# gcr_me13 register map
Registers are access not given, no defined reset value unless marked. A register's access mark holds for its fields unless they carry their own. Offsets are from the block's base; lines under a group give offsets from that group; [hi:lo] are bit positions; {n}, {i} and the like mark numbered series; 'fields as' and 'values as' point back to an identical list; <NAME> marks a mode.

## Memory map
0x40000000 GCR size 0x400 — Global Control Registers.

## GCR — Global Control Registers.
Base 0x40000000
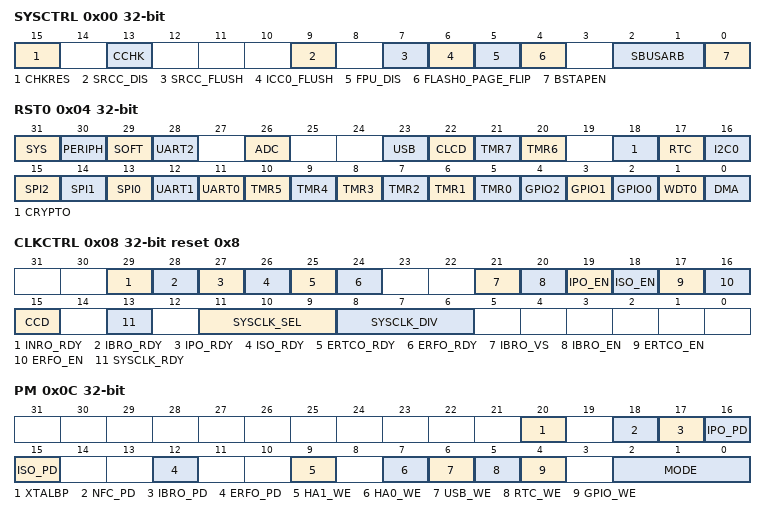
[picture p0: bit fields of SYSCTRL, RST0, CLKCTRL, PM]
0x00 SYSCTRL — System Control.
  [15] CHKRES — ROM Checksum Result. This bit is only valid when CHKRD=1.
    0=pass (ROM Checksum Correct.); 1=fail (ROM Checksum Fail.)
  [13] CCHK — Compute ROM Checksum. This bit is self-cleared when calculation is completed. Once set, software clearing this bit is ignored and the bit will remain set until the operation is completed.
    0=complete (No operation/complete.); 1=Start operation
  [9] SRCC_DIS — Data Cache Disable. The system cache (s) will be completely disabled when this bit is set.
    0=en (Is enabled.); 1=dis (Is Disabled.)
  [7] SRCC_FLUSH — Data Cache Flush. The system cache (s) will be flushed when this bit is set.
    0=Normal System Cache Operation; 1=flush (System Cache is flushed)
  [6] ICC0_FLUSH — Code Cache Flush. This bit is used to flush the code caches and the instruction buffer of the Cortex-M4.
    0=Normal Code Cache Operation; 1=flush (Code Caches and CPU instruction buffer are flushed)
  [5] FPU_DIS — Cortex M4 Floating Point Disable This bit is used to disable the floating-point unit of the Cortex-M4.
  [4] FLASH0_PAGE_FLIP — Flips the Flash bottom and top halves. (Depending on the total flash size, each half is either 256K or 512K). Initiating a flash page flip will cause a flush of both the data buffer on the DCODE bus and the internal instruction buffer.
    0=normal (Physical layout matches logical layout.); 1=swapped (Bottom half mapped to logical top half and vice versa.)
  [2:1] SBUSARB — System bus abritration scheme. These bits are used to select between Fixed-burst abritration and Round-Robin scheme. The Round-Robin scheme is selected by default. These bits are reset by the system reset.
    0=fix (Fixed Burst abritration.); 1=Round-robin scheme
  [0] BSTAPEN — Boundary Scan TAP enable. When enabled, the JTAG port is connected to the Boundary Scan TAP. Otherwise, the port is connected to the ARM ICE function. This bit is reset by the POR. Reset value and access depend on the part number.
    0=dis (Boundary Scan TAP port disabled.); 1=en (Boundary Scan TAP port enabled.)
0x04 RST0 — Reset.
  [31] SYS — System Reset. Setting this bit to 1 resets the CPU core and all peripherals, including the watchdog timer.
  [30] PERIPH — Peripheral Reset. Setting this bit to 1 resets all peripherals. The CPU core, the watchdog timer, and all GPIO pins are unaffected by this reset.
  [29] SOFT — Soft Reset. Setting this bit to 1 resets everything except the CPU and the watchdog timer.
  [28] UART2 — UART2 Reset. Setting this bit to 1 resets all UART 2 blocks.
  [26] ADC — Analog to Digital Reset.
  [23] USB — USB Reset. Setting this bit resets both USB blocks.
  [22] CLCD — CLCD Reset. Setting this bit to 1 resets the CLCD block.
  [21] TMR7 — Timer7 Reset. Setting this bit to 1 resets Timer 7 blocks.
  [20] TMR6 — Timer6 Reset. Setting this bit to 1 resets Timer 6 blocks.
  [18] CRYPTO — Cryptographic Reset. Setting this bit to 1 resets the AES block, the SHA block and the DES block.
  [17] RTC — Real Time Clock Reset.
  [16] I2C0 — I2C0 Reset.
  [15] SPI2 — SPI2 Reset. Setting this bit to 1 resets all SPI 2 blocks.
  [14] SPI1 — SPI1 Reset. Setting this bit to 1 resets all SPI 1 blocks.
  [13] SPI0 — SPI0 Reset. Setting this bit to 1 resets all SPI 0 blocks.
  [12] UART1 — UART1 Reset. Setting this bit to 1 resets all UART 1 blocks.
  [11] UART0 — UART0 Reset. Setting this bit to 1 resets all UART 0 blocks.
  [n+5] TMR{n} (n=0..5) — Timer{n} Reset. Setting this bit to 1 resets Timer {n} blocks.
  [4] GPIO2 — GPIO2 Reset. Setting this bit to 1 resets GPIO2 pins to their default states.
  [3] GPIO1 — GPIO1 Reset. Setting this bit to 1 resets GPIO1 pins to their default states.
  [2] GPIO0 — GPIO0 Reset. Setting this bit to 1 resets GPIO0 pins to their default states.
  [1] WDT0 — Watchdog Timer Reset.
  [0] DMA — DMA Reset.
0x08 CLKCTRL reset 0x8 — Clock Control.
  [29] INRO_RDY ro — Internal Nano Ring Oscillator Low Frequency Reference Clock Ready.
    0=not (Is not Ready.); 1=ready (Is Ready.)
  [28] IBRO_RDY ro — Internal Baud Rate Oscillator Ready.
    0=not (Is not Ready.); 1=ready (Is Ready.)
  [27] IPO_RDY ro — Internal Primary Oscillator Ready.
    0=not (Is not Ready.); 1=ready (Is Ready.)
  [26] ISO_RDY ro — 60MHz ISO Ready.
    0=not (Is not Ready.); 1=ready (Is Ready.)
  [25] ERTCO_RDY ro — 32kHz Crystal Oscillator Ready
    0=not (Is not Ready.); 1=ready (Is Ready.)
  [24] ERFO_RDY ro — 27MHz Crystal Oscillator Ready
    0=not (Is not Ready.); 1=ready (Is Ready.)
  [21] IBRO_VS — 7.3728MHz Internal Oscillator Voltage Source Select
  [20] IBRO_EN — 8MHz High Frequency Internal Reference Clock Enable.
  [19] IPO_EN — 96MHz High Frequency Internal Reference Clock Enable.
  [18] ISO_EN — 60MHz High Frequency Internal Reference Clock Enable.
  [17] ERTCO_EN — 32kHz Crystal Oscillator Enable.
  [16] ERFO_EN — 27MHz Crystal Oscillator Enable.
    0=dis (Is Disabled.); 1=en (Is Enabled.)
  [15] CCD ro — Cryptographic clock divider
    0=non_div (The cryptographic accelerator clock is running in non-divided mode.); 1=div (The cryptographic accelerator clock is running in divided mode.)
  [13] SYSCLK_RDY ro — Clock Ready. This read only bit reflects whether the currently selected system clock source is running.
    0=busy (Switchover to the new clock source (as selected by CLKSEL) has not yet occurred.); 1=ready (System clock running from CLKSEL clock source.)
  [11:9] SYSCLK_SEL — Clock Source Select. This 3 bit field selects the source for the system clock.
    0=ISO (Internal Secondary Oscilatior Clock); 2=ERFO (27MHz Crystal is used for the system clock.); 3=INRO (8kHz Internal Nano Ring Oscillator is used for the system clock.); 4=IPO (The internal Primary oscillator is used for the system clock.); 5=IBRO (The internal Baud Rate oscillator is used for the system clock.); 6=ERTCO (32kHz is used for the system clock.)
  [8:6] SYSCLK_DIV — Prescaler Select. This 3 bit field sets the system operating frequency by controlling the prescaler that divides the output of the PLL0.
    0=div1 (Divide by 1.); 1=div2 (Divide by 2.); 2=div4 (Divide by 4.); 3=div8 (Divide by 8.); 4=div16 (Divide by 16.); 5=div32 (Divide by 32.); 6=div64 (Divide by 64.); 7=div128 (Divide by 128.)
0x0C PM — Power Management.
  [20] XTALBP — XTAL Bypass
    0=normal; 1=bypass
  [18] NFC_PD — When set, the NFC radio becomes inactive when the upon entering DEEPSLEEP mode
    0=active (Mode is Active.); 1=deepsleep (Powered down in DEEPSLEEP.)
  [17] IBRO_PD — Internal Baud Rate Oscillator power down. This bit selects the power state in DEEPSLEEP mode.
    values as NFC_PD
  [16] IPO_PD — Internal Primary Oscilatory power down. This bit selects the power state in DEEPSLEEP mode.
    values as NFC_PD
  [15] ISO_PD — Internal Secondary Oscilator Power Down. This bit selects the power state in DEEPSLEEP mode.
    values as NFC_PD
  [12] ERFO_PD — Radio Frequency oscilator Crystal Power Down. This bit selects the power state in DEEPSLEEP mode.
    values as NFC_PD
  [9] HA1_WE — Hardware Accelerator 1 Wake Up Enable. This bit enables USB activity as wakeup source.
  [7] HA0_WE — Hardware Accelerator 0 Wake Up Enable. This bit enables USB activity as wakeup source.
  [6] USB_WE — USB Wake Up Enable. This bit enables USB activity as wakeup source.
  [5] RTC_WE — RTC Alarm Wake Up Enable. This bit enables RTC alarm as wakeup source. If enabled, the desired RTC alarm must be configured via the RTC control registers.
  [4] GPIO_WE — GPIO Wake Up Enable. This bit enables all GPIO pins as potential wakeup sources. Any GPIO configured for wakeup is capable of causing an exit from IDLE or STANDBY modes when this bit is set.
  [2:0] MODE — Operating Mode. This two bit field selects the current operating mode for the device. Note that code execution only occurs during ACTIVE mode.
    0=Active Mode; 2=DeepSleep Mode; 3=Shutdown Mode; 4=Backup Mode
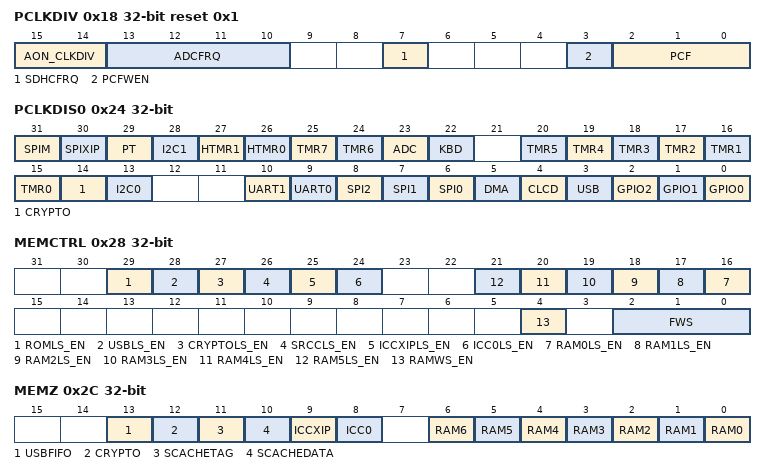
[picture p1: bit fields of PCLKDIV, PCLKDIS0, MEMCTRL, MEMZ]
0x18 PCLKDIV reset 0x1 — Peripheral Clock Divider.
  [15:14] AON_CLKDIV — Always-ON (AON) domain CLock Divider. These bits define the AON domain clock divider.
    0=div_4 (PCLK divide by 4.); 1=div_8 (PCLK divide by 8.); 2=div_16 (PCLK divide by 16.); 3=div_32 (PCLK divide by 32.)
  [13:10] ADCFRQ — ADC clock Frequency. These bits define the ADC clock frequency. FADC = FPCLK/ (ADCFRQ).
  [7] SDHCFRQ — SDHC Clock Frequency. This bits defines the clock frequency of SDHC.
    0=48MHz; 1=24MHz
  [3] PCFWEN — PCF Write Enable. This bit allows the PCF Register bits to be updated by Software.
    0=blocked (Writes to PCF are blocked.); 1=allowed (Writes to PCF are allowed)
  [2:0] PCF — These bits determine the clock frequency for the UART, I2C and Key Pad peripherals. These peripherals have an adaptive clock generator that dynamically adjusts the peripheral frequency based on the main system bus frequency. These bits are dynamically updated when the PLL0 is selected as the system clock source and are set by hardware. These bits determine the clock frequency for the UART, I2C and Key Pad peripherals. These peripherals have an adaptive clock generator that dynamically adjusts the peripheral frequency based on the main system bus frequency. These bits are dynamically updated when the PLL0 is selected as the system clock source and are set by hardware.
    2=96MHz; 3=48MHz; 4=24MHz; 5=12MHz; 6=6MHz; 7=3MHz
0x24 PCLKDIS0 — Peripheral Clock Disable.
  [all] fields
    0=en (enable it.); 1=dis (disable it.)
  [31] SPIM — SPI XiP Master Controller Disable.
  [30] SPIXIP — SPI XiP Disable.
  [29] PT — PT Clock Disable.
  [28] I2C1 — I2C 1 Disable.
  [27] HTMR1 — HTimer 1 Disable.
  [26] HTMR0 — HTimer 0 Disable.
  [25] TMR7 — Timer 7 Disable.
  [24] TMR6 — Timer 6 Disable.
  [23] ADC — ADC Disable.
  [22] KBD — Secure Keyboard Disable.
  [n+15] TMR{n} (n=0..5) — Timer {n} Disable.
  [14] CRYPTO — Crypto Disable.
  [13] I2C0 — I2C 0 Disable.
  [10] UART1 — UART 1 Disable.
  [9] UART0 — UART 0 Disable.
  [8] SPI2 — SPI 2 Disable.
  [7] SPI1 — SPI 1 Disable.
  [6] SPI0 — SPI 0 Disable.
  [5] DMA — DMA Disable.
  [4] CLCD — CLCD Disable.
  [3] USB — USB Disable.
  [2] GPIO2 — GPIO2 Disable.
  [1] GPIO1 — GPIO1 Disable.
  [0] GPIO0 — GPIO0 Clock Disable.
0x28 MEMCTRL — Memory Clock Control Register.
  [29] ROMLS_EN — ROM Light Sleep Mode.
    0=active (RAM is active.); 1=light_sleep (RAM is in Light Sleep mode.)
  [28] USBLS_EN — USB FIFO Light Sleep Mode.
    values as ROMLS_EN
  [27] CRYPTOLS_EN — CRYPTO RAM Light Sleep Mode.
    values as ROMLS_EN
  [26] SRCCLS_EN — SysCache RAM Light Sleep Mode.
    values as ROMLS_EN
  [25] ICCXIPLS_EN — ICACHE-XIP RAM Light Sleep Mode.
    values as ROMLS_EN
  [24] ICC0LS_EN — ICache RAM Light Sleep Mode.
    values as ROMLS_EN
  [n+16] RAM{n}LS_EN (n=0..5) — System RAM {n} Light Sleep Mode.
    values as ROMLS_EN
  [4] RAMWS_EN — SRAM Wait State Enable
  [2:0] FWS — Flash Wait State. These bits define the number of wait-state cycles per Flash data read access. Minimum wait state is 2.
0x2C MEMZ — Memory Zeroize Control.
  [all] fields
    0=nop (No operation/complete.); 1=Start operation
  [13] USBFIFO — USB FIFO Zeroization.
  [12] CRYPTO — Crypto (MAA) Memory.
  [11] SCACHETAG — System Cache Tag Zeroization.
  [10] SCACHEDATA — System Cache Data Ram Zeroization.
  [9] ICCXIP — Instruction Cache XIP Data and Tag Ram zeroizatoin.
  [8] ICC0 — Instruction Cache.
  [n] RAM{n} (n=0..6) — System RAM Block {n}.
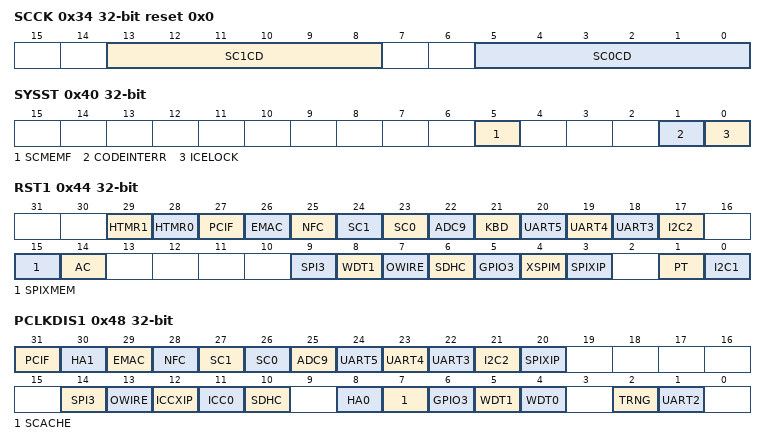
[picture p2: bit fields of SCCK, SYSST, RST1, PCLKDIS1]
0x34 SCCK reset 0x0 — Smart Card Clock Control.
  [13:8] SC1CD — Smart Card1 Clock Divider
  [5:0] SC0CD — Smart Card0 Clock Divider
0x40 SYSST — System Status Register.
  [5] SCMEMF — System Cache Memory Fault Flag. This bit indicates a memory fault has occurred in the System Cache while receiving data from the Hyperbus Interface.
    0=Normal Operating Condition; 1=Memory Fault
  [1] CODEINTERR — Code Integrity Error Flag. This bit indicates a code integrity error has occurred in XiP interface.
    0=Normal Operating Condition; 1=Code Integrity Error
  [0] ICELOCK — ARM ICE Lock Status.
    0=unlocked (ICE is unlocked.); 1=locked (ICE is locked.)
0x44 RST1 — Reset 1.
  [29] HTMR1 — HTIMER1 Reset.
  [28] HTMR0 — HTIMER0 Reset.
  [27] PCIF — PCIF Reset.
  [26] EMAC — EMAC Reset.
  [25] NFC — NFC Reset.
  [24] SC1 — SC1 Reset.
  [23] SC0 — SC0 Reset.
  [22] ADC9 — ADC9 Reset.
  [21] KBD — KBD Reset.
  [20] UART5 — UART5 Reset.
  [19] UART4 — UART4 Reset.
  [18] UART3 — UART3 Reset.
  [17] I2C2 — I2C2 Reset.
  [15] SPIXMEM — SPIXMEM Reset.
  [14] AC — AC Reset.
  [9] SPI3 — SPI3 Reset.
  [8] WDT1 — WDT1 Reset.
  [7] OWIRE — OWIRE Reset.
  [6] SDHC — SDHC/SDIO Reset.
  [5] GPIO3 — GPIO3 Reset.
  [4] XSPIM — GSPI XiP Master Controller Reset.
  [3] SPIXIP — SPI XiP Master Reset.
  [1] PT — PT Reset.
  [0] I2C1 — I2C1 Reset.
0x48 PCLKDIS1 — Peripheral Clock Disable.
  [all] fields
    0=en (Enable.); 1=dis (Disable.)
  [31] PCIF — PCIF Clock Disable
  [30] HA1 — Hardware Accelerator 1 Clock Disable
  [29] EMAC — EMAC Clock Disable
  [28] NFC — NFC Clock Disable
  [27] SC1 — SC1 Clock Disable
  [26] SC0 — SC0 Clock Disable
  [25] ADC9 — ADC9 Clock Disable
  [24] UART5 — UART5 Clock Disable
  [23] UART4 — UART4 Clock Disable
  [22] UART3 — UART3 Clock Disable
  [21] I2C2 — I2C2 Clock Disable
  [20] SPIXIP — SPI-XIP Data Clock Disable
  [14] SPI3 — SPI3 Clock Disable.
  [13] OWIRE — One-Wire Clock Disable.
  [12] ICCXIP — ICache XIP Clock Disable.
  [11] ICC0 — ICache Clock Disable.
  [10] SDHC — SDHC/SDIO Clock Disable.
  [8] HA0 — Hardware Accelerator 0 Clock Disable.
  [7] SCACHE — System Cache Clock Disable.
  [6] GPIO3 — GPIO3 Disable
  [5] WDT1 — WDT1 Clock Disable
  [4] WDT0 — WDT0 Clock Disable
  [2] TRNG — TRNG Disable.
  [1] UART2 — UART2 Disable.
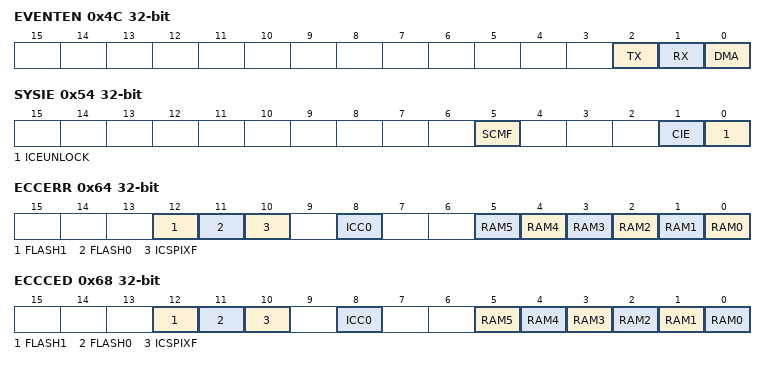
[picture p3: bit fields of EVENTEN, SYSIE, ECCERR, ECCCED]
0x4C EVENTEN — Event Enable Register.
  [2] TX — Enable TXEV pin event. When this bit is set, TXEV event from the CPU is output to GPIO[25].
  [1] RX — Enable RXEV pin event. When this bit is set, a logic high of GPIO0[24] will cause an RXEV event to wake the CPU from WFE sleep mode.
  [0] DMA — Enable DMA event. When this bit is set, a DMA event will cause an RXEV event to wake the CPU from WFE sleep mode.
0x50 REVISION ro
  [15:0] REVISION — Manufacturer Chip Revision.
0x54 SYSIE — System Status Interrupt Enable Register.
  [all] fields
    0=dis (disabled.); 1=en (enabled.)
  [5] SCMF — System Cache Memory Fault Interrupt Enable.
  [1] CIE — Code Integrity Error Interrupt Enable.
  [0] ICEUNLOCK — ARM ICE Unlock Interrupt Enable.
0x58 IPOCNT — IPO Warmup Count Register.
  [9:0] WMUPCNT
0x64 ECCERR — ECC Error Register
  [12] FLASH1 — ECC Flash1 Error Flag. Write 1 to clear.
  [11] FLASH0 — ECC Flash0 Error Flag. Write 1 to clear.
  [10] ICSPIXF — ECC SFCC Instruction Cache Error Flag. Write 1 to clear.
  [8] ICC0 — ECC Icache0 Error Flag. Write 1 to clear.
  [n] RAM{n} (n=0..5) — ECC System RAM{n} Error Flag. Write 1 to clear.
0x68 ECCCED — ECC Not Double Error Detect Register
  [12] FLASH1 — ECC Flash1 Not Double Error Detect. Write 1 to clear.
  [11] FLASH0 — ECC Flash0 Not Double Error Detect. Write 1 to clear.
  [10] ICSPIXF — ECC IcacheXIP Not Double Error Detect. Write 1 to clear.
  [8] ICC0 — ECC Icache0 Not Double Error Detect. Write 1 to clear.
  [n] RAM{n} (n=1..5) — ECC System RAM{n} Not Double Error Detect. Write 1 to clear.
  [0] RAM0 — ECC System RAM0 Error Flag. Write 1 to clear.
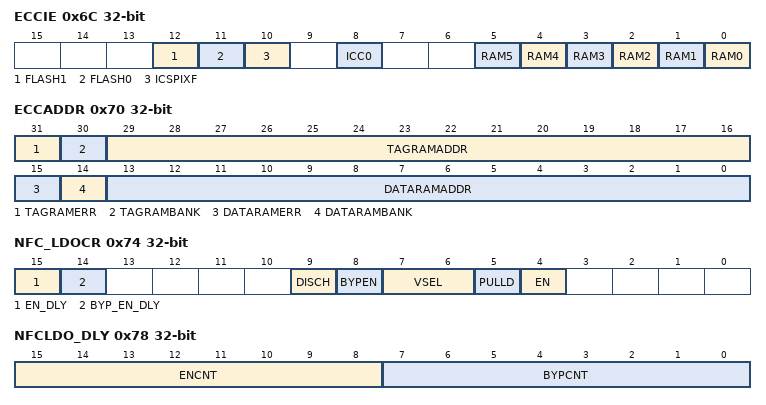
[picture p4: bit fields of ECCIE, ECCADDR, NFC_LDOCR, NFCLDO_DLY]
0x6C ECCIE — ECC IRQ Enable Register
  [12] FLASH1 — ECC Flash1 Interrupt Enable.
  [11] FLASH0 — ECC Flash0 Interrupt Enable.
  [10] ICSPIXF — ECC IcacheXIP Interrupt Enable.
  [8] ICC0 — ECC Icache0 Interrupt Enable.
  [n] RAM{n} (n=0..5) — ECC System RAM{n} Interrupt Enable.
0x70 ECCADDR — ECC Error Address Register
  [31] TAGRAMERR — TAG RAM ERROR
  [30] TAGRAMBANK — ECC Error Address/TAG RAM Error Bank
  [29:16] TAGRAMADDR — ECC Error Address/TAG RAM Error Address
  [15] DATARAMERR — DATA RAM ERROR
  [14] DATARAMBANK — ECC Error Address/DATA RAM Error Bank
  [13:0] DATARAMADDR — ECC Error Address/DATA RAM Error Address
0x74 NFC_LDOCR — NFC LDO Control Register
  [15] EN_DLY
  [14] BYP_EN_DLY
  [9] DISCH
  [8] BYPEN — Bypass enable
  [7:6] VSEL — Voltage Selection for NFC LDO
  [5] PULLD — Enabled the dedicated NFC LDO pin pulldown
  [4] EN — Enabled the dedicated NFC LDO
0x78 NFCLDO_DLY — NFC LDO Delay Register
  [15:8] ENCNT, [7:0] BYPCNT
